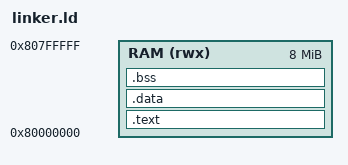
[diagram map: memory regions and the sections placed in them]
/*
 * Copyright 2026 Yuehhsin Sung
 *
 * SPDX-License-Identifier: Apache-2.0
 */

ENTRY(_start)

MEMORY
{
    RAM (rwx) : ORIGIN = 0x80000000, LENGTH = 8M
}

SECTIONS
{
    .text : {
        KEEP(*(.vectors))
        *(.text.init)
        KEEP(*(.text.FreeRTOS_IRQ_Handler*))
        KEEP(*(.text.FreeRTOS_SWI_Handler*))
        *(.text*)
        *(.rodata*)
    } > RAM

    .data : {
        *(.data*)
    } > RAM

    .bss : {
        . = ALIGN(8);
        __bss_start = .;
        *(.bss*)
        *(COMMON)
        . = ALIGN(8);
        __bss_end = .;
    } > RAM

    . = ALIGN(16);
    _stack_top = ORIGIN(RAM) + LENGTH(RAM);
}
